# EDMA3CC register map
Vendor: Texas Instruments
Registers are 32-bit, access per field, no defined reset value unless marked. A register's access mark holds for its fields unless they carry their own. Offsets are as the file gives them; [hi:lo] are bit positions; lines under a group give offsets from that group; {n}, {i} and the like mark numbered series; 'fields as' and 'values as' point back to an identical list.

## EDMA3CC (part 2 of 3)
0x00 PID 16-bit ro — The peripheral identification register (PID) uniquely identifies the EDMA3CC and the specific revision of the EDMA3CC.
  [15:0] PID — Peripheral identifier uniquely identifies the EDMA3CC and the specific revision of the EDMA3CC. [[br]]Value 0 to FFFF FFFFh. [[br]]Reset value for PID[31] to PID[16] is 4001h. [[br]]Peripheral identifier uniquely identifies the EDMA3CC and the specific revision of the EDMA3CC. [[br]]Value 0 to FFFF FFFFh. [[br]]Reset value for PID[15] to PID[0] is 4C00h.
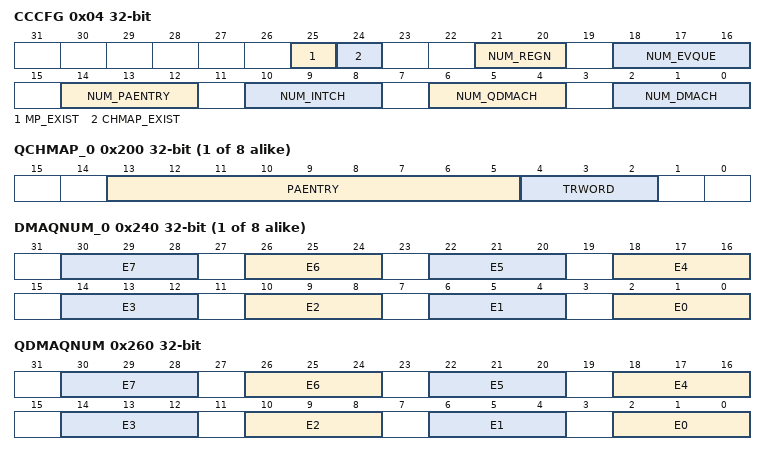
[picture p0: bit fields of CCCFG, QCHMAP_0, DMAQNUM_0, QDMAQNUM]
0x04 CCCFG ro — The EDMA3CC configuration register (CCCFG) provides the features/resources for the EDMA3CC in a particular device.
  [25] MP_EXIST — Memory protection existence.
    1=en_2_0x1 (Memory protection logic included.); 0=en_1_0x0 (Reserved.)
  [24] CHMAP_EXIST — Channel mapping existence.
    1=en_2_0x1 (Channel mapping logic included.); 0=en_1_0x0 (Reserved.)
  [21:20] NUM_REGN — Number of MP and shadow regions.
    3=en_4_0x3 (Reserved.); 2=en_3_0x2 (4 regions.); 1=en_2_0x1 (Reserved); 0=en_1_0x0 (Reserved.)
  [18:16] NUM_EVQUE — Number of queues/number of TCs.
    7=en_5_0x7 (Reserved.); 3=en_4_0x3 (Reserved from 3h to 7h.); 2=en_3_0x2 (3 EDMA3TCs/Event Queues); 1=en_2_0x1 (Reserved.); 0=en_1_0x0 (Reserved.)
  [14:12] NUM_PAENTRY — Number of PaRAM sets.
    7=en_5_0x7 (Reserved.); 5=en_4_0x5 (Reserved from 5h to 7h.); 4=en_3_0x4 (256 PaRAM sets.); 3=en_2_0x3 (Reserved); 0=en_1_0x0 (Reserved from 0h to 3h.)
  [10:8] NUM_INTCH — Number of interrupt channels.
    7=en_5_0x7 (Reserved.); 5=en_4_0x5 (Reserved from 5h to 7.); 4=en_3_0x4 (64 interrupt channels.); 3=en_2_0x3 (Reserved.); 0=en_1_0x0 (Reserved from 0h to 3h.)
  [6:4] NUM_QDMACH — Number of QDMA channels.
    7=en_5_0x7 (Reserved.); 5=en_4_0x5 (Reserved from 5h to 7.); 4=en_3_0x4 (8 QDMA channels.); 3=en_2_0x3 (Reserved.); 0=en_1_0x0 (Reserved from 0h to 3h.)
  [2:0] NUM_DMACH — Number of DMA channels.
    7=en_5_0x7 (Reserved.); 6=en_4_0x6 (Reserved.); 5=en_3_0x5 (64 DMA channels.); 4=en_2_0x4 (Reserved.); 0=en_1_0x0 (Reserved from 0h to 4h.)
0x10 SYSCONFIG — The EDMA3CC system configuration register is used for clock management configuration.
  [3:2] IDLEMODE rw — Configuration of the local target state management mode. [[br]]By definition, target can handle read/write transaction as long as it is out of IDLE state. [[br]]
    3=en_4_0x3 (Smart-idle wakeup-capable mode: local target's idle state eventually follows (acknowledges) the system's idle requests, depending on the IP module's internal requirements. IP module may generate (IRQ- or DMA-request-related) wakeup events when in idle state. Mode is only relevant if the appropriate IP module "swakeup" output(s) is (are) implemented.); 2=en_3_0x2 (Smart-idle mode: local target's idle state eventually follows (acknowledges) the system's idle requests, depending on the IP module's internal requirements. IP module shall not generate (IRQ- or DMA-request-related) wakeup events.); 1=en_2_0x1 (No-idle mode: local target never enters idle state. Backup mode, for debug only.); 0=en_1_0x0 (Force-idle mode: local target's idle state follows (acknowledges) the system's idle requests unconditionally, i.e. regardless of the IP module's internal requirements. Backup mode, for debug only.)
{0x100+4i} DCHMAP_{i} (i=0..63)
  [13:5] PAENTRY rw — Points to the PaRAM set number for DMA channel n. [[br]]Value 0 to FFh.
{0x200+4i} QCHMAP_{i} (i=0..7) — Each QDMA channel in EDMA3CC can be associated with any PaRAM set available on the device. Furthermore, the specific trigger word (0-7) of the PaRAM set can be programmed. The PaRAM set association and trigger word for every QDMA channel register is configurable using the QDMA channel map register (QCHMAPn). At reset the QDMA channel map registers for all QDMA channels point to PaRAM set 0. If an application makes use of both a DMA channel that points to PaRAM set 0 and any QDMA channels, ensure that QCHMAP is programmed appropriately to point to a different PaRAM entry.
  [13:5] PAENTRY rw — PAENTRY points to the PaRAM set number for QDMA channel .
    1=en_2_0x1 (Reserved, from 100h to 1FFh. Always write 0 to this bit. Writes of 1 to this bit are not supported and attempts to do so may result in undefine behavior.); 0=en_1_0x0 (Parameter entry 0 through 255, from 0 to FFh.)
  [4:2] TRWORD rw — Points to the specific trigger word of the PaRAM set defined by PAENTRY. [[br]]A write to the trigger word results in a QDMA event being recognized.
{0x240+4i} DMAQNUM_{i} (i=0..7) — The DMA channel queue number register (DMAQNUMn) allows programmability of each of the 64 DMA channels in the EDMA3CC to submit its associated synchronization event to any event queue in the EDMA3CC. At reset, all channels point to event queue 0. Because the event queues in EDMA3CC have a fixed association to the transfer controllers, that is, Q0 TRs are submitted to TC0, Q1 TRs are submitted to TC1, etc., by programming DMAQNUM for a particular DMA channel also dictates which transfer controller is utilized for the data movement (or which EDMA3TC receives the TR request).
  [all] fields
    7=en_5_0x7 (Reserved. Always write 0 to this bit; writes of 1 to this bit are not supported and attempts to do so may result in undefined behavior.); 3=en_4_0x3 (Reserved, from 3h to 7h. Always write 0 to this bit; writes of 1 to this bit are not supported and attempts to do so may result in undefined behavior.); 2=en_3_0x2 (Event n is queued on Q2.); 1=en_2_0x1 (Event n is queued on Q1.); 0=en_1_0x0 (Event n is queued on Q0.)
  [4n+2:4n] E{n} rw (n=0..7) — DMA queue number. [[br]]Contains the event queue number to be used for the corresponding DMA channel. [[br]]Programming DMAQNUM for an event queue number to a value more then the number of queues available in the EDMA3CC results in undefined behavior. [[br]]On DMAQNUM0, E[{4n+2}] to E[{4n}] is E{n}. [[br]]On DMAQNUM1, E[{4n+2}] to E[{4n}] is E{n+8}. [[br]]On DMAQNUM2, E[{4n+2}] to E[{4n}] is E{n+16}. [[br]]On DMAQNUM3, E[{4n+2}] to E[{4n}] is E{n+24}. [[br]]On DMAQNUM4, E[{4n+2}] to E[{4n}] is E{n+32}. [[br]]On DMAQNUM5, E[{4n+2}] to E[{4n}] is E{n+40}. [[br]]On DMAQNUM6, E[{4n+2}] to E[{4n}] is E{n+48}. [[br]]On DMAQNUM7, E[{4n+2}] to E[{4n}] is E{n+56}. [[br]]
0x260 QDMAQNUM — The QDMA channel queue number register (QDMAQNUMn) is used to program all the QDMA channels in the EDMA3CC to submit the associated QDMA event to any of the event queues in the EDMA3CC.
  [all] fields
    values as the fields of DMAQNUM_0
  [4n+2:4n] E{n} rw (n=0..7) — QDMA queue number. [[br]]Contains the event queue number to be used for the corresponding QDMA channel.
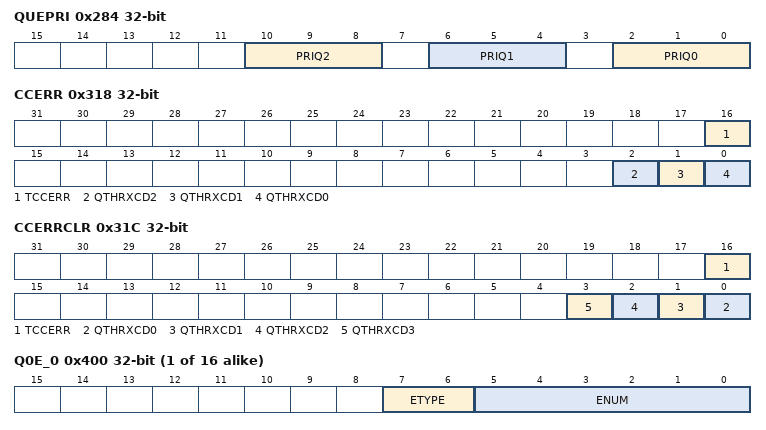
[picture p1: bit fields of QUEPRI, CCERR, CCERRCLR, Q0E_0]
0x284 QUEPRI — The queue priority register (QUEPRI) allows you to change the priority of the individual queues and the priority of the transfer request (TR) associated with the events queued in the queue. Because the queue to EDMA3TC mapping is fixed, programming QUEPRI essentially governs the priority of the associated transfer controller(s) read/write commands with respect to the other bus masters in the device. You can modify the EDMA3TC priority to obtain the desired system performance.
  [10:8] PRIQ2 rw — Priority level for queue 2. [[br]]Dictates the priority level used by TC2 relative to other masters in the device. [[br]]A value of 0 means highest priority and a value of 7 means lowest priority.
  [6:4] PRIQ1 rw — Priority level for queue 1. [[br]]Dictates the priority level used by TC1 relative to other masters in the device. [[br]]A value of 0 means highest priority and a value of 7 means lowest priority.
  [2:0] PRIQ0 rw — Priority level for queue 0. [[br]]Dictates the priority level used by TC0 relative to other masters in the device. [[br]]A value of 0 means highest priority and a value of 7 means lowest priority.
0x300 EMR ro — For a particular DMA channel, if a second event is received prior to the first event getting cleared/serviced, the bit corresponding to that channel is set/asserted in the event missed registers (EMR/EMRH). All trigger types are treated individually, that is, manual triggered (ESR/ESRH), chain triggered (CER/CERH), and event triggered (ER/ERH) are all treated separately. The EMR/EMRH bits for a channel are also set if an event on that channel encounters a NULL entry (or a NULL TR is serviced). If any EMR/EMRH bit is set (and all errors, including bits in other error registers (QEMR, CCERR) were previously cleared), the EDMA3CC generates an error interrupt. For details on EDMA3CC error interrupt generation, see Error Interrupts. This register is part of a set of registers that provide information on missed DMA and/or QDMA events, and instances when event queue thresholds are exceeded. If any of the bits in these registers is set, it results in the EDMA3CC generating an error interrupt.
  [31:0] En — Channel 0 to 31 event missed. [[br]]En is cleared by writing a 1 to the corresponding bit in the event missed clear register (EMCR). [[br]]
    1=en_2_0x1 (Missed event occurred.); 0=en_1_0x0 (No missed event.)
0x304 EMRH ro — For a particular DMA channel, if a second event is received prior to the first event getting cleared/serviced, the bit corresponding to that channel is set/asserted in the event missed registers (EMR/EMRH). All trigger types are treated individually, that is, manual triggered (ESR/ESRH), chain triggered (CER/CERH), and event triggered (ER/ERH) are all treated separately. The EMR/EMRH bits for a channel are also set if an event on that channel encounters a NULL entry (or a NULL TR is serviced). If any EMR/EMRH bit is set (and all errors, including bits in other error registers (QEMR, CCERR) were previously cleared), the EDMA3CC generates an error interrupt. For details on EDMA3CC error interrupt generation, see Error Interrupts. This register is part of a set of registers that provide information on missed DMA and/or QDMA events, and instances when event queue thresholds are exceeded. If any of the bits in these registers is set, it results in the EDMA3CC generating an error interrupt.
  [31:0] En — Channel 32 to 63 event missed. [[br]]En is cleared by writing a 1 to the corresponding bit in the event missed clear register high (EMCRH). [[br]]
    values as EMR.En
0x308 EMCR wo — Once a missed event is posted in the event missed registers (EMR/EMRH), the bit remains set and you need to clear the set bit(s). This is done by way of CPU writes to the event missed clear registers (EMCR/EMCRH). Writing a 1 to any of the bits clears the corresponding missed event (bit) in EMR/EMRH; writing a 0 has no effect. This register is part of a set of registers that provide information on missed DMA and/or QDMA events, and instances when event queue thresholds are exceeded. If any of the bits in these registers is set, it results in the EDMA3CC generating an error interrupt.
  [31:0] En — Event missed 0 to 31 clear. [[br]]All error bits must be cleared before additional error interrupts will be asserted by the EDMA3CC. [[br]]
    1=en_2_0x1 (Corresponding missed event bit in the event missed register (EMR) is cleared (En = 0).); 0=en_1_0x0 (No effect.)
0x30C EMCRH wo — Once a missed event is posted in the event missed registers (EMR/EMRH), the bit remains set and you need to clear the set bit(s). This is done by way of CPU writes to the event missed clear registers (EMCR/EMCRH). Writing a 1 to any of the bits clears the corresponding missed event (bit) in EMR/EMRH; writing a 0 has no effect. This register is part of a set of registers that provide information on missed DMA and/or QDMA events, and instances when event queue thresholds are exceeded. If any of the bits in these registers is set, it results in the EDMA3CC generating an error interrupt.
  [31:0] En — Event missed 32 to 63 clear. [[br]]All error bits must be cleared before additional error interrupts will be asserted by the EDMA3CC. [[br]]
    1=en_2_0x1 (Corresponding missed event bit in the event missed register high (EMRH) is cleared (En = 0).); 0=en_1_0x0 (No effect.)
0x310 QEMR ro — For a particular QDMA channel, if two QDMA events are detected without the first event getting cleared/serviced, the bit corresponding to that channel is set/asserted in the QDMA event missed register (QEMR). The QEMR bits for a channel are also set if a QDMA event on the channel encounters a NULL entry (or a NULL TR is serviced). If any QEMR bit is set (and all errors, including bits in other error registers (EMR/EMRH, CCERR) were previously cleared), the EDMA3CC generates an error interrupt. For details on EDMA3CC error interrupt generation, see Error Interrupts. This register is part of a set of registers that provide information on missed DMA and/or QDMA events, and instances when event queue thresholds are exceeded. If any of the bits in these registers is set, it results in the EDMA3CC generating an error interrupt.
  [7:0] En — Channel 0 to 7 QDMA event missed. [[br]]En is cleared by writing a 1 to the corresponding bit in the QDMA event missed clear register (QEMCR). [[br]]
    values as EMR.En
0x314 QEMCR — Once a missed event is posted in the QDMA event missed registers (QEMR), the bit remains set and you need to clear the set bit(s). This is done by way of CPU writes to the QDMA event missed clear registers (QEMCR). Writing a 1 to any of the bits clears the corresponding missed event (bit) in QEMR; writing a 0 has no effect. This register is part of a set of registers that provide information on missed DMA and/or QDMA events, and instances when event queue thresholds are exceeded. If any of the bits in these registers is set, it results in the EDMA3CC generating an error interrupt.
  [7:0] En wo — QDMA event missed clear. [[br]]All error bits must be cleared before additional error interrupts will be asserted by the EDMA3CC. [[br]]
    1=en_2_0x1 (Corresponding missed event bit in the QDMA event missed register (QEMR) is cleared (En= 0).); 0=en_1_0x0 (No effect.)
0x318 CCERR ro — The EDMA3CC error register (CCERR) indicates whether or not at any instant of time the number of events queued up in any of the event queues exceeds or equals the threshold/watermark value that is set in the queue watermark threshold register (QWMTHRA). Additionally, CCERR also indicates if when the number of outstanding TRs that have been programmed to return transfer completion code (TRs which have the TCINTEN or TCCHEN bit in OPT set) to the EDMA3CC has exceeded the maximum allowed value of 63. If any bit in CCERR is set (and all errors, including bits in other error registers (EMR/EMRH, QEMR) were previously cleared), the EDMA3CC generates an error interrupt. For details on EDMA3CC error interrupt generation, see Error Interrupts. Once the error bits are set in CCERR, they can only be cleared by writing to the corresponding bits in the EDMA3CC error clear register (CCERRCLR). This register is part of a set of registers that provide information on missed DMA and/or QDMA events, and instances when event queue thresholds are exceeded. If any of the bits in these registers is set, it results in the EDMA3CC generating an error interrupt.
  [16] TCCERR — Transfer completion code error. [[br]]TCCERR is cleared by writing a 1 to the corresponding bit in the EDMA3CC error clear register (CCERRCLR). [[br]]
    1=en_2_0x1 (Total number of allowed TCCs has been reached.); 0=en_1_0x0 (Total number of allowed TCCs outstanding has not been reached.)
  [2] QTHRXCD2 — Queue threshold error for queue 2. [[br]]QTHRXCD2 is cleared by writing a 1 to the corresponding bit in the EDMA3CC error clear register (CCERRCLR). [[br]]
    1=en_2_0x1 (Watermark/threshold has been exceeded.); 0=en_1_0x0 (Watermark/threshold has not been exceeded.)
  [1] QTHRXCD1 — Queue threshold error for queue 1 . [[br]]QTHRXCD1 is cleared by writing a 1 to the corresponding bit in the EDMA3CC error clear register (CCERRCLR). [[br]]
    values as QTHRXCD2
  [0] QTHRXCD0 — Queue threshold error for queue 0. [[br]]QTHRXCD0 is cleared by writing a 1 to the corresponding bit in the EDMA3CC error clear register (CCERRCLR). [[br]]
    values as QTHRXCD2
0x31C CCERRCLR — The EDMA3CC error clear register (CCERRCLR) is used to clear any error bits that are set in the EDMA3CC error register (CCERR). In addition, CCERRCLR also clears the values of some bit fields in the queue status registers (QSTATn) associated with a particular event queue. Writing a 1 to any of the bits clears the corresponding bit in CCERR; writing a 0 has no effect. This register is part of a set of registers that provide information on missed DMA and/or QDMA events, and instances when event queue thresholds are exceeded. If any of the bits in these registers is set, it results in the EDMA3CC generating an error interrupt.
  [16] TCCERR wo — Transfer completion code error clear.
    1=en_2_0x1 (Clears the TCCERR bit in the EDMA3CC error register (CCERR).); 0=en_1_0x0 (No effect.)
  [n] QTHRXCD{n} wo (n=0..3) — Queue threshold error clear for queue {n}.
    1=en_2_0x1 (Clears the QTHRXCD{n} bit in the EDMA3CC error register (CCERR) and the WM and THRXCD bits in the queue status register {n} (QSTAT{n}).); 0=en_1_0x0 (No effect.)
0x320 EEVAL — The EDMA3CC error interrupt is asserted whenever an error bit is set in any of the error registers (EMR/EMRH, QEMR, and CCERR). For subsequent error bits that get set, the EDMA3CC error interrupt is reasserted only when transitioning from an all the error bits cleared to at least one error bit is set . Alternatively, a CPU write of 1 to the EVAL bit in the error evaluation register (EEVAL) results in reasserting the EDMA3CC error interrupt, if there are any outstanding error bits set due to subsequent error conditions. Writes of 0 have no effect. This register is part of a set of registers that provide information on missed DMA and/or QDMA events, and instances when event queue thresholds are exceeded. If any of the bits in these registers is set, it results in the EDMA3CC generating an error interrupt.
  [0] EVAL wo — Error interrupt evaluate.
    1=en_2_0x1 (Write 1 to clear interrupts when all error registers have been cleared. EDMA3CC error interrupt will remain if any errors have not been cleared in any of the error registers (EMR/EMRH, CCERR, QEMR)); 0=en_1_0x0 (No effect.)
{0x340+8i} DRAE{i} rw (i=0..7) — The DMA region access enable register for shadow region {i} is programmed to allow or disallow read/write accesses on a bit-by-bit bases for all DMA registers in the shadow region {i} view of the DMA channel registers. Additionally, the DRAE{i} configuration determines completion of which DMA channels will result in assertion of the shadow region {i} DMA completion interrupt. The DRAE registers are part of the group of the region access enable registers, which includes DRAEm and QRAEm. Where m is the number of shadow regions in the EDMA3CC memory map for a device. You can configure these registers to assign ownership of DMA/QDMA channels to a particular shadow region.
  [31:0] En — DMA region access enable for bit 31 to 0 in region {i}.
    1=en_2_0x1 (Accesses via region {i} address space to bit 31 to 0 in any DMA channel register are allowed. Reads return the value from bit n and writes modify the state of bit 31 to 0. Enabled interrupt bits for bit n contribute to the generation of a transfer completion interrupt for shadow region {i}.); 0=en_1_0x0 (Accesses via region {i} address space to bit 31 to 0 in any DMA channel register are not allowed. Reads return 0 on bit n and writes do not modify the state of bit 31 to 0. Enabled interrupt bits for bit n do not contribute to the generation of a transfer completion interrupt for shadow region {i}.)
{0x344+8i} DRAEH{i} rw (i=0..7) — The DMA region access enable register for shadow region {i} is programmed to allow or disallow read/write accesses on a bit-by-bit bases for all DMA registers in the shadow region {i} view of the DMA channel registers. Additionally, the DRAE{i} configuration determines completion of which DMA channels will result in assertion of the shadow region {i} DMA completion interrupt. The DRAE registers are part of the group of the region access enable registers, which includes DRAEm and QRAEm. Where m is the number of shadow regions in the EDMA3CC memory map for a device. You can configure these registers to assign ownership of DMA/QDMA channels to a particular shadow region.
  [31:0] En — DMA region access enable for bit 63 to 32 in region {i}.
    1=en_2_0x1 (Accesses via region {i} address space to bit 63 to 32 in any DMA channel register are allowed. Reads return the value from bit n and writes modify the state of bit 63 to 32. Enabled interrupt bits for bit 31 to 0 contribute to the generation of a transfer completion interrupt for shadow region {i}.); 0=en_1_0x0 (Accesses via region {i} address space to bit 63 to 32 in any DMA channel register are not allowed. Reads return 0 on bit n and writes do not modify the state of bit 63 to 32. Enabled interrupt bits for bit 31 to 0 do not contribute to the generation of a transfer completion interrupt for shadow region {i}.)
{0x380+4i} QRAE_{i} (i=0..7) — The QDMA region access enable register for shadow region m (QRAEm) is programmed to allow or disallow read/write accesses on a bit-by-bit bases for all QDMA registers in the shadow region m view of the QDMA registers. This includes all 4-bit QDMA registers. The QRAE register is part of the group of the region access enable registers, which includes DRAEm and QRAEm. Where m is the number of shadow regions in the EDMA3CC memory map for a device. You can configure these registers to assign ownership of DMA/QDMA channels to a particular shadow region.
  [7:0] En rw — QDMA region access enable for bit n/QDMA channel n in region m.
    1=en_2_0x1 (Accesses via region m address space to bit n in any QDMA channel register are allowed. Reads return the value from bit n and writes modify the state of bit n.); 0=en_1_0x0 (Accesses via region m address space to bit n in any QDMA channel register are not allowed. Reads return 0 on bit n and writes do not modify the state of bit n.)
{0x400+4i} Q0E_{i} ro (i=0..15) — The event queue entry registers (QxEy) exist for all 16 queue entries (the maximum allowed queue entries) for all event queues in the EDMA3CC. The event queue entry registers range from Q0E0 to Q0E15, Q1E0 to Q1E15, and Q2E0 to Q2E15. Each register details the event number (ENUM) and the event type (ETYPE). For example, if the value in Q1E4 is read as 000 004Fh, this means the 4th entry in queue 1 is a manually-triggered event on DMA channel 15. The Q0E0 register provides visibility into the event queues and a TR life cycle. These are useful for system debug as they provide in-depth visibility for the events queued up in the event queue and also provide information on what parts of the EDMA3CC logic are active once the event has been received by the EDMA3CC.
  [7:6] ETYPE — Event entry y in queue 0. [[br]]Specifies the specific event type for the given entry in the event queue. [[br]]
    1=en_2_0x1 (Auto-triggered via QER.); 0=en_1_0x0 (Event triggered via ER.)
  [5:0] ENUM — Event entry y in queue 0. [[br]]Event number: QDMA channel number (0 to 3). [[br]]DMA channel/event number (0 to 63).
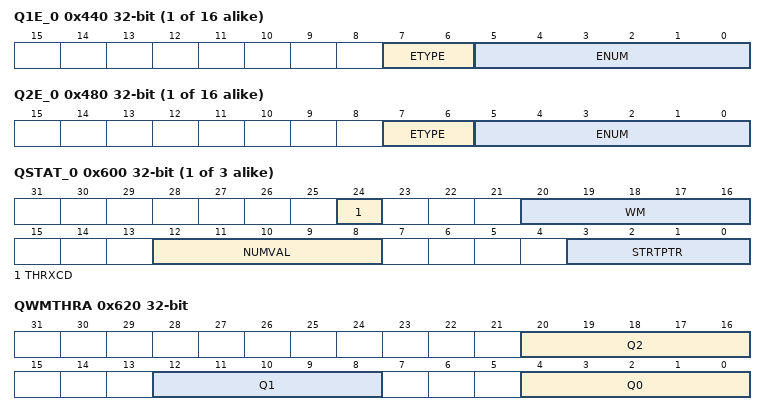
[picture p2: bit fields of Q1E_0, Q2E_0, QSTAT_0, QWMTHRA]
{0x440+4i} Q1E_{i} ro (i=0..15) — The event queue entry registers (QxEy) exist for all 16 queue entries (the maximum allowed queue entries) for all event queues in the EDMA3CC. The event queue entry registers range from Q0E0 to Q0E15, Q1E0 to Q1E15, and Q2E0 to Q2E15. Each register details the event number (ENUM) and the event type (ETYPE). For example, if the value in Q1E4 is read as 000 004Fh, this means the 4th entry in queue 1 is a manually-triggered event on DMA channel 15. The Q1E0 register provides visibility into the event queues and a TR life cycle. These are useful for system debug as they provide in-depth visibility for the events queued up in the event queue and also provide information on what parts of the EDMA3CC logic are active once the event has been received by the EDMA3CC.
  [7:6] ETYPE — Event entry y in queue 1. [[br]]Specifies the specific event type for the given entry in the event queue. [[br]]
    values as Q0E_0.ETYPE
  [5:0] ENUM — Event entry y in queue 1. [[br]]Event number: QDMA channel number (0 to 3). [[br]]DMA channel/event number (0 to 63).
{0x480+4i} Q2E_{i} ro (i=0..15) — The event queue entry registers (QxEy) exist for all 16 queue entries (the maximum allowed queue entries) for all event queues in the EDMA3CC. The event queue entry registers range from Q0E0 to Q0E15, Q1E0 to Q1E15, and Q2E0 to Q2E15. Each register details the event number (ENUM) and the event type (ETYPE). For example, if the value in Q1E4 is read as 000 004Fh, this means the 4th entry in queue 1 is a manually-triggered event on DMA channel 15. The Q2E0 register provides visibility into the event queues and a TR life cycle. These are useful for system debug as they provide in-depth visibility for the events queued up in the event queue and also provide information on what parts of the EDMA3CC logic are active once the event has been received by the EDMA3CC.
  [7:6] ETYPE — Event entry y in queue 2. [[br]]Specifies the specific event type for the given entry in the event queue. [[br]]
    values as Q0E_0.ETYPE
  [5:0] ENUM — Event entry y in queue 2. [[br]]Event number: QDMA channel number (0 to 3). [[br]]DMA channel/event number (0 to 63).
{0x600+4i} QSTAT_{i} ro (i=0..2) — The queue status register (QSTAT) provides visibility into the event queues and a TR life cycle. These are useful for system debug as they provide in-depth visibility for the events queued up in the event queue and also provide information on what parts of the EDMA3CC logic are active once the event has been received by the EDMA3CC.
  [24] THRXCD — Threshold exceeded. [[br]]THRXCD is cleared by writing a 1 to the corresponding QTHRXCDn bit in the EDMA3CC error clear register (CCERRCLR). [[br]]
    1=en_2_0x1 (Threshold specified by the Qn bit in the queue watermark threshold A register (QWMTHRA) has been exceeded.); 0=en_1_0x0 (Threshold specified by the Qn bit in the queue watermark threshold A register (QWMTHRA) has not been exceeded.)
  [20:16] WM — Watermark for maximum queue usage. [[br]]Watermark tracks the most entries that have been in queue n since reset or since the last time that the watermark (WM) bit was cleared. [[br]]WM is cleared by writing a 1 to the corresponding QTHRXCDn bit in the EDMA3CC error clear register (CCERRCLR). [[br]]
    1=en_2_0x1 (Reserved, from 11h to 1Fh. Always write 0 to this bit; writes of 1 to this bit are not supported and attempts to do so may result in undefined behavior.); 0=en_1_0x0 (Legal values are 0 (empty) to 10h (full).)
  [12:8] NUMVAL — Number of valid entries in queue n. [[br]]The total number of entries residing in the queue manager FIFO at a given instant. [[br]]Always enabled. [[br]]
    values as WM
  [3:0] STRTPTR — Start pointer. [[br]]The offset to the head entry of queue n, in units of entries. [[br]]Always enabled. [[br]]Legal values are 0 (0th entry) to Fh (15th entry).
0x620 QWMTHRA — The queue watermark threshold A register (QWMTHRA) provides visibility into the event queues and a TR life cycle. These are useful for system debug as they provide in-depth visibility for the events queued up in the event queue and also provide information on what parts of the EDMA3CC logic are active once the event has been received by the EDMA3CC.
  [all] fields
    18=en_3_0x12 (From 12h to 1Fh, Reserved. Always write 0 to this bit; writes of 1 to this bit are not supported and attempts to do so may result in undefined behavior.); 17=en_2_0x11 (Disables the threshold errors.); 0=en_1_0x0 (From 0h to 10h, The default is 16 (maximum allowed).)
  [20:16] Q2 rw — Queue threshold for queue 2 value. [[br]]The QTHRXCD2 bit in the EDMA3CC error register (CCERR) and the THRXCD bit in the queue status register 2 (QSTAT2) are set when the number of events in queue 2 at an instant in time (visible via the NUMVAL bit in QSTAT2) equals or exceeds the value specified by Q2. [[br]]
  [12:8] Q1 rw — Queue threshold for queue 1 value. [[br]]The QTHRXCD1 bit in the EDMA3CC error register (CCERR) and the THRXCD bit in the queue status register 1 (QSTAT1) are set when the number of events in queue 1 at an instant in time (visible via the NUMVAL bit in QSTAT1) equals or exceeds the value specified by Q1. [[br]]
  [4:0] Q0 rw — Queue threshold for queue 0 value. [[br]]The QTHRXCD0 bit in the EDMA3CC error register (CCERR) and the THRXCD bit in the queue status register 0 (QSTAT0) are set when the number of events in queue 0 at an instant in time (visible via the NUMVAL bit in QSTAT0) equals or exceeds the value specified by Q0. [[br]]
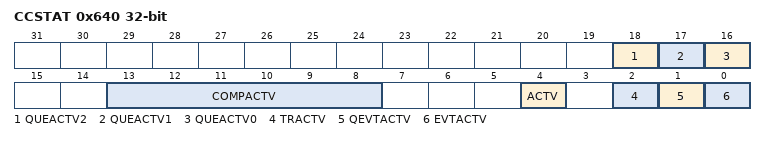
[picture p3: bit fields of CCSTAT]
0x640 CCSTAT ro — The EDMA3CC status register (CCSTAT) has a number of status bits that reflect which parts of the EDMA3CC logic is active at any given instant of time. CCSTAT provides visibility into the event queues and a TR life cycle. These are useful for system debug as they provide in-depth visibility for the events queued up in the event queue and also provide information on what parts of the EDMA3CC logic are active once the event has been received by the EDMA3CC.
  [18] QUEACTV2 — Queue 2 active.
    1=en_2_0x1 (At least one TR is queued in queue 2.); 0=en_1_0x0 (No events are queued in queue 2.)
  [17] QUEACTV1 — Queue 1 active.
    1=en_2_0x1 (At least one TR is queued in queue 1.); 0=en_1_0x0 (No events are queued in queue 1.)
  [16] QUEACTV0 — Queue 0 active.
    1=en_2_0x1 (At least one TR is queued in queue 0.); 0=en_1_0x0 (No events are queued in queue 0.)
  [13:8] COMPACTV — Completion request active. [[br]]The COMPACTV field reflects the count for the number of completion requests submitted to the transfer controllers. [[br]]This count increments every time a TR is submitted and is programmed to report completion (the TCINTEN or TCCCHEN bits in OPT in the parameter entry associated with the TR are set). [[br]]The counter decrements for every valid TCC received back from the transfer controllers. [[br]]If at any time the count reaches a value of 63, the EDMA3CC will not service any new TRs until the count is less then 63 (or return a transfer completion code from a transfer controller, which would decrement the count). [[br]]
    1=en_2_0x1 (Total of 1 completion request to 63 completion requests are outstanding, from 1h to 3Fh.); 0=en_1_0x0 (No completion requests outstanding.)
  [4] ACTV — Channel controller active. [[br]]Channel controller active is a logical-OR of each of the *ACTV bits. [[br]]The ACTV bit remains high through the life of a TR. [[br]]
    1=en_2_0x1 (Channel is busy.); 0=en_1_0x0 (Channel is idle..)
  [2] TRACTV — Transfer request active.
    1=en_2_0x1 (Transfer request processing/submission logic is active.); 0=en_1_0x0 (Transfer request processing/submission logic is inactive.)
  [1] QEVTACTV — QDMA event active.
    1=en_2_0x1 (At least one enabled QDMA event (QER) is active within the EDMA3CC.); 0=en_1_0x0 (No enabled QDMA events are active within the EDMA3CC.)
  [0] EVTACTV — DMA event active.
    1=en_2_0x1 (At least one enabled DMA event (ER and EER, ESR, CER) is active within the EDMA3CC.); 0=en_1_0x0 (No enabled DMA events are active within the EDMA3CC.)
